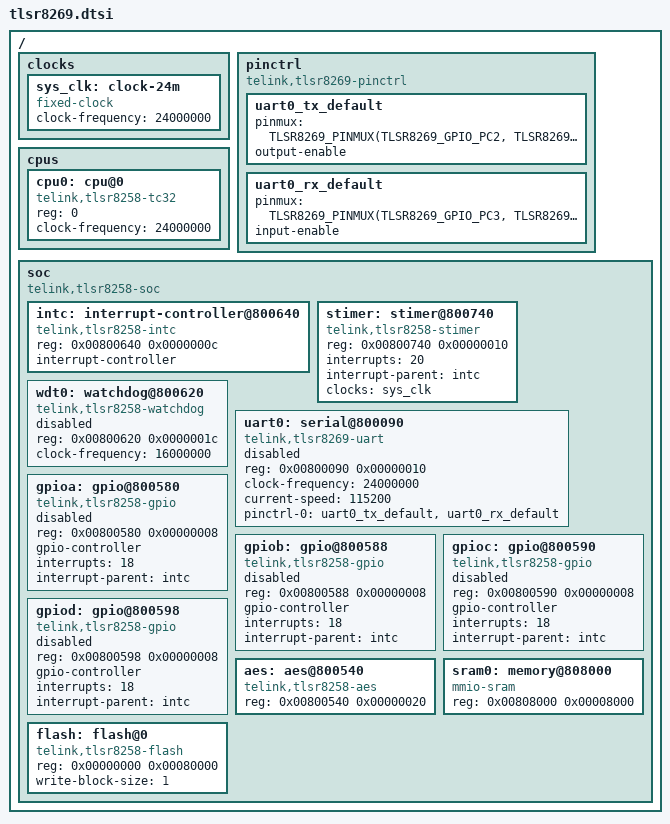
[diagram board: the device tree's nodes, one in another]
/*
 * SPDX-FileCopyrightText: Copyright The Zephyr Project Contributors
 * SPDX-License-Identifier: Apache-2.0
 */

/*
 * TLSR8269 (826x series). Only blocks whose register layout matches the
 * TLSR8258 driver are described here, with the 8258 compatibles. UART and
 * the 802.15.4 radio differ on 826x and need their own bindings and
 * drivers before they can be added.
 */

#include <zephyr/dt-bindings/pinctrl/tlsr8269-pinctrl.h>

/ {
	#address-cells = <1>;
	#size-cells = <1>;

	clocks {
		sys_clk: clock-24m {
			compatible = "fixed-clock";
			#clock-cells = <0>;
			clock-frequency = <24000000>;
		};
	};

	pinctrl: pinctrl {
		compatible = "telink,tlsr8269-pinctrl";

		/* UART pins of the vendor EVK (board_826x_evk.h). */
		uart0_tx_default: uart0_tx_default {
			pinmux = <TLSR8269_PINMUX(TLSR8269_GPIO_PC2,
						  TLSR8269_FUNC_UART)>;
			output-enable;
		};

		uart0_rx_default: uart0_rx_default {
			pinmux = <TLSR8269_PINMUX(TLSR8269_GPIO_PC3,
						  TLSR8269_FUNC_UART)>;
			input-enable;
		};
	};

	cpus {
		#address-cells = <1>;
		#size-cells = <0>;

		cpu0: cpu@0 {
			compatible = "telink,tlsr8258-tc32";
			reg = <0>;
			clock-frequency = <24000000>;
		};
	};

	soc {
		#address-cells = <1>;
		#size-cells = <1>;
		compatible = "telink,tlsr8258-soc";
		ranges;

		intc: interrupt-controller@800640 {
			compatible = "telink,tlsr8258-intc";
			reg = <0x00800640 0x0000000c>;
			interrupt-controller;
			#interrupt-cells = <1>;
		};

		stimer: stimer@800740 {
			compatible = "telink,tlsr8258-stimer";
			reg = <0x00800740 0x00000010>;
			interrupts = <20>;
			interrupt-parent = <&intc>;
			clocks = <&sys_clk>;
		};

		wdt0: watchdog@800620 {
			compatible = "telink,tlsr8258-watchdog";
			reg = <0x00800620 0x0000001c>;
			clock-frequency = <16000000>;
			status = "disabled";
		};

		uart0: serial@800090 {
			compatible = "telink,tlsr8269-uart";
			reg = <0x00800090 0x00000010>;
			clock-frequency = <24000000>;
			current-speed = <115200>;
			pinctrl-0 = <&uart0_tx_default &uart0_rx_default>;
			pinctrl-names = "default";
			status = "disabled";
		};

		gpioa: gpio@800580 {
			compatible = "telink,tlsr8258-gpio";
			reg = <0x00800580 0x00000008>;
			gpio-controller;
			#gpio-cells = <2>;
			interrupts = <18>;
			interrupt-parent = <&intc>;
			status = "disabled";
		};

		gpiob: gpio@800588 {
			compatible = "telink,tlsr8258-gpio";
			reg = <0x00800588 0x00000008>;
			gpio-controller;
			#gpio-cells = <2>;
			interrupts = <18>;
			interrupt-parent = <&intc>;
			status = "disabled";
		};

		gpioc: gpio@800590 {
			compatible = "telink,tlsr8258-gpio";
			reg = <0x00800590 0x00000008>;
			gpio-controller;
			#gpio-cells = <2>;
			interrupts = <18>;
			interrupt-parent = <&intc>;
			status = "disabled";
		};

		gpiod: gpio@800598 {
			compatible = "telink,tlsr8258-gpio";
			reg = <0x00800598 0x00000008>;
			gpio-controller;
			#gpio-cells = <2>;
			interrupts = <18>;
			interrupt-parent = <&intc>;
			status = "disabled";
		};

		aes: aes@800540 {
			compatible = "telink,tlsr8258-aes";
			reg = <0x00800540 0x00000020>;
		};

		sram0: memory@808000 {
			compatible = "mmio-sram";
			reg = <0x00808000 0x00008000>;
		};

		flash: flash@0 {
			compatible = "telink,tlsr8258-flash";
			reg = <0x00000000 0x00080000>;
			write-block-size = <1>;
		};
	};
};
